# PIC16F18877 register map
File version: 1.0
Registers are 8-bit, read-write, reset 0x0 unless marked. A register's access mark holds for its fields unless they carry their own. Offsets are from the block's base; [hi:lo] are bit positions; {n}, {i} and the like mark numbered series; 'fields as' and 'values as' point back to an identical list.

## COMPARATORS
Base 0x0080098F
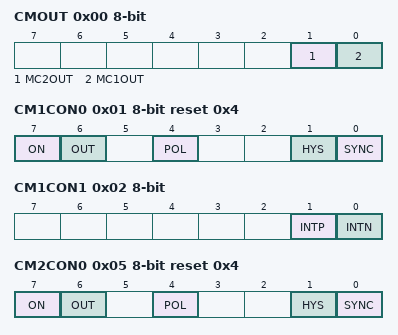
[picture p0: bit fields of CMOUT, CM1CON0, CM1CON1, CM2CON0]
0x00 CMOUT — CMOUT, data address 0x98f
  [1] MC2OUT, [0] MC1OUT
0x01 CM1CON0 reset 0x4 — CM1CON0, data address 0x990
  [7] ON, [6] OUT, [4] POL, [1] HYS, [0] SYNC
0x02 CM1CON1 — CM1CON1, data address 0x991
  [1] INTP, [0] INTN
0x03 CM1NSEL — CM1NSEL, data address 0x992
  [2:0] NCH
0x04 CM1PSEL (reset mask 0x7) — CM1PSEL, data address 0x993
  [3:0] PCH
0x05 CM2CON0 reset 0x4 — CM2CON0, data address 0x994
  [7] ON, [6] OUT, [4] POL, [1] HYS, [0] SYNC
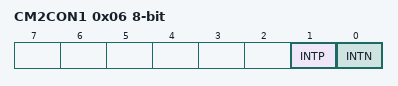
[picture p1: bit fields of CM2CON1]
0x06 CM2CON1 — CM2CON1, data address 0x995
  [1] INTP, [0] INTN
0x07 CM2NSEL — CM2NSEL, data address 0x996
  [2:0] NCH
0x08 CM2PSEL (reset mask 0x7) — CM2PSEL, data address 0x997
  [3:0] PCH

## EUSART
Base 0x00800119
0x00 RC1REG — RC1REG, data address 0x119
0x01 TX1REG — TX1REG, data address 0x11a
0x02 SP1BRGL — SP1BRGL, data address 0x11b
0x03 SP1BRGH — SP1BRGH, data address 0x11c
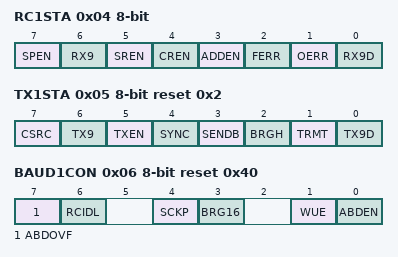
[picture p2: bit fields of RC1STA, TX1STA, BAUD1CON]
0x04 RC1STA — RC1STA, data address 0x11d
  [7] SPEN, [6] RX9, [5] SREN, [4] CREN, [3] ADDEN, [2] FERR, [1] OERR, [0] RX9D
0x05 TX1STA reset 0x2 — TX1STA, data address 0x11e
  [7] CSRC, [6] TX9, [5] TXEN, [4] SYNC, [3] SENDB, [2] BRGH, [1] TRMT, [0] TX9D
0x06 BAUD1CON reset 0x40 — BAUD1CON, data address 0x11f
  [7] ABDOVF, [6] RCIDL, [4] SCKP, [3] BRG16, [1] WUE, [0] ABDEN

## INTERRUPTS — Interrupt flags and enables
Base 0x0080070C
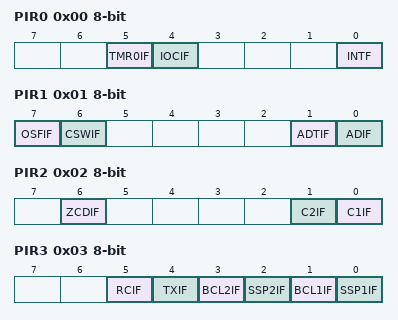
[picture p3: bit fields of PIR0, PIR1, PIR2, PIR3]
0x00 PIR0 — PIR0, data address 0x70c
  [5] TMR0IF, [4] IOCIF, [0] INTF
0x01 PIR1 — PIR1, data address 0x70d
  [7] OSFIF, [6] CSWIF, [1] ADTIF, [0] ADIF
0x02 PIR2 — PIR2, data address 0x70e
  [6] ZCDIF, [1] C2IF, [0] C1IF
0x03 PIR3 — PIR3, data address 0x70f
  [5] RCIF, [4] TXIF, [3] BCL2IF, [2] SSP2IF, [1] BCL1IF, [0] SSP1IF
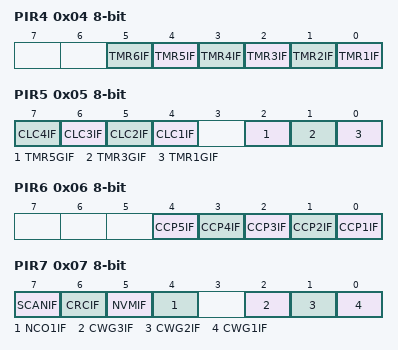
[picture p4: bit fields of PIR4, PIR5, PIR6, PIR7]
0x04 PIR4 — PIR4, data address 0x710
  [n-1] TMR{n}IF (n=1..6)
0x05 PIR5 — PIR5, data address 0x711
  [n+3] CLC{n}IF (n=1..4), [2] TMR5GIF, [1] TMR3GIF, [0] TMR1GIF
0x06 PIR6 — PIR6, data address 0x712
  [n-1] CCP{n}IF (n=1..5)
0x07 PIR7 — PIR7, data address 0x713
  [7] SCANIF, [6] CRCIF, [5] NVMIF, [4] NCO1IF, [2] CWG3IF, [1] CWG2IF, [0] CWG1IF
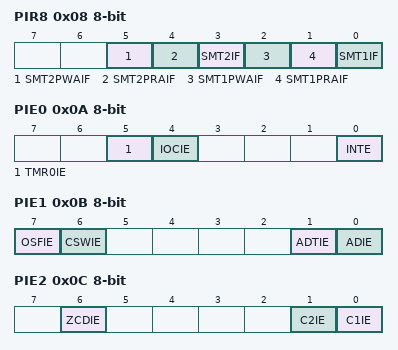
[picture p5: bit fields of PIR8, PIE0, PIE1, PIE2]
0x08 PIR8 — PIR8, data address 0x714
  [5] SMT2PWAIF, [4] SMT2PRAIF, [3] SMT2IF, [2] SMT1PWAIF, [1] SMT1PRAIF, [0] SMT1IF
0x0A PIE0 — PIE0, data address 0x716
  [5] TMR0IE, [4] IOCIE, [0] INTE
0x0B PIE1 — PIE1, data address 0x717
  [7] OSFIE, [6] CSWIE, [1] ADTIE, [0] ADIE
0x0C PIE2 — PIE2, data address 0x718
  [6] ZCDIE, [1] C2IE, [0] C1IE
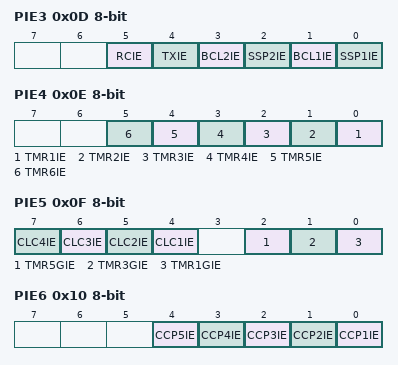
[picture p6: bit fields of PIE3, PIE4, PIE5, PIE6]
0x0D PIE3 — PIE3, data address 0x719
  [5] RCIE, [4] TXIE, [3] BCL2IE, [2] SSP2IE, [1] BCL1IE, [0] SSP1IE
0x0E PIE4 — PIE4, data address 0x71a
  [n-1] TMR{n}IE (n=1..6)
0x0F PIE5 — PIE5, data address 0x71b
  [n+3] CLC{n}IE (n=1..4), [2] TMR5GIE, [1] TMR3GIE, [0] TMR1GIE
0x10 PIE6 — PIE6, data address 0x71c
  [n-1] CCP{n}IE (n=1..5)
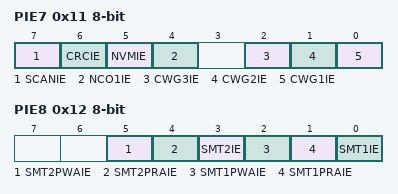
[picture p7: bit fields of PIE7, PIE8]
0x11 PIE7 — PIE7, data address 0x71d
  [7] SCANIE, [6] CRCIE, [5] NVMIE, [4] NCO1IE, [2] CWG3IE, [1] CWG2IE, [0] CWG1IE
0x12 PIE8 — PIE8, data address 0x71e
  [5] SMT2PWAIE, [4] SMT2PRAIE, [3] SMT2IE, [2] SMT1PWAIE, [1] SMT1PRAIE, [0] SMT1IE

## MSSP — Synchronous serial port
Base 0x0080018C
0x00 SSP1BUF reset not defined — SSP1BUF, data address 0x18c
  [7:0] SSPBUF
0x01 SSP1ADD — SSP1ADD, data address 0x18d
  [7:0] SSPADD
0x02 SSP1MSK reset 0xFF — SSP1MSK, data address 0x18e
  [7:0] SSPMSK
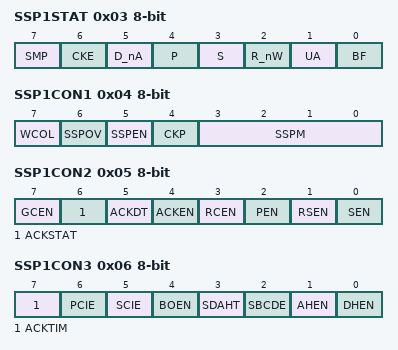
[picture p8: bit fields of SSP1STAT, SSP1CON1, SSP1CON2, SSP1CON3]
0x03 SSP1STAT — SSP1STAT, data address 0x18f
  [7] SMP, [6] CKE, [5] D_nA, [4] P, [3] S, [2] R_nW, [1] UA, [0] BF
0x04 SSP1CON1 — SSP1CON1, data address 0x190
  [7] WCOL, [6] SSPOV, [5] SSPEN, [4] CKP, [3:0] SSPM
0x05 SSP1CON2 — SSP1CON2, data address 0x191
  [7] GCEN, [6] ACKSTAT, [5] ACKDT, [4] ACKEN, [3] RCEN, [2] PEN, [1] RSEN, [0] SEN
0x06 SSP1CON3 — SSP1CON3, data address 0x192
  [7] ACKTIM, [6] PCIE, [5] SCIE, [4] BOEN, [3] SDAHT, [2] SBCDE, [1] AHEN, [0] DHEN
0x0A SSP2BUF reset not defined — SSP2BUF, data address 0x196
  [7:0] SSPBUF
0x0B SSP2ADD — SSP2ADD, data address 0x197
  [7:0] SSPADD
0x0C SSP2MSK reset 0xFF — SSP2MSK, data address 0x198
  [7:0] SSPMSK
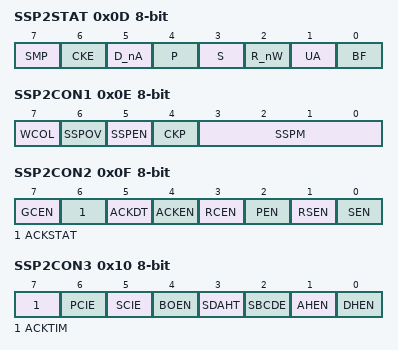
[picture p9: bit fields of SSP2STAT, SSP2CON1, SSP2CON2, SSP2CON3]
0x0D SSP2STAT — SSP2STAT, data address 0x199
  [7] SMP, [6] CKE, [5] D_nA, [4] P, [3] S, [2] R_nW, [1] UA, [0] BF
0x0E SSP2CON1 — SSP2CON1, data address 0x19a
  [7] WCOL, [6] SSPOV, [5] SSPEN, [4] CKP, [3:0] SSPM
0x0F SSP2CON2 — SSP2CON2, data address 0x19b
  fields as SSP1CON2
0x10 SSP2CON3 — SSP2CON3, data address 0x19c
  fields as SSP1CON3
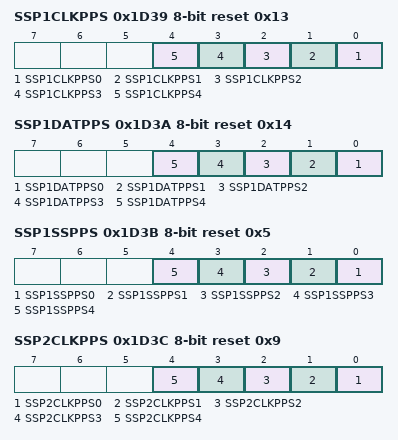
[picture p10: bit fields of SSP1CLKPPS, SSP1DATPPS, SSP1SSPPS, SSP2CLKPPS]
0x1D39 SSP1CLKPPS reset 0x13 — SSP1CLKPPS, data address 0x1ec5
  [n] SSP1CLKPPS{n} (n=0..4)
0x1D3A SSP1DATPPS reset 0x14 — SSP1DATPPS, data address 0x1ec6
  [n] SSP1DATPPS{n} (n=0..4)
0x1D3B SSP1SSPPS reset 0x5 — SSP1SSPPS, data address 0x1ec7
  [n] SSP1SSPPS{n} (n=0..4)
0x1D3C SSP2CLKPPS reset 0x9 — SSP2CLKPPS, data address 0x1ec8
  [n] SSP2CLKPPS{n} (n=0..4)
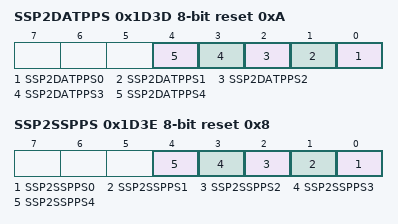
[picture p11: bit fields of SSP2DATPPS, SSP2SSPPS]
0x1D3D SSP2DATPPS reset 0xA — SSP2DATPPS, data address 0x1ec9
  [n] SSP2DATPPS{n} (n=0..4)
0x1D3E SSP2SSPPS reset 0x8 — SSP2SSPPS, data address 0x1eca
  [n] SSP2SSPPS{n} (n=0..4)
